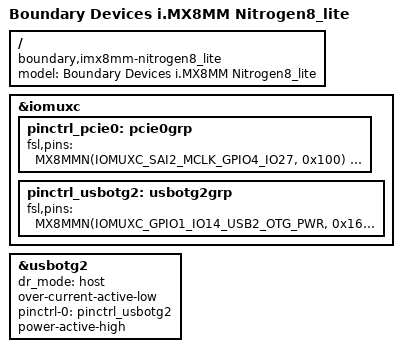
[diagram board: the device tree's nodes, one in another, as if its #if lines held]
// SPDX-License-Identifier: (GPL-2.0+ OR MIT)
/*
 * Copyright 2018 Boundary Devices
 */

/dts-v1/;
#ifdef CONFIG_DEFCONFIG
#define UBOOT
#endif
#define IMX8MM

#define MX8MMN(a, b)	MX8MM_##a b
#define IMX8MMN(a)	IMX8MM_##a
#define IMX8MN_CLK_LCDIF_PIXEL IMX8MN_CLK_DISP_PIXEL_ROOT
#include <dt-bindings/phy/phy-imx8-pcie.h>
#include "imx8mm.dtsi"
#include "imx8mmn-nitrogen8_lite.dtsi"

&iomuxc {
	pinctrl_pcie0: pcie0grp {
		fsl,pins = <
#define GP_PCIE0_RESET		<&gpio4 27 GPIO_ACTIVE_LOW>
			MX8MMN(IOMUXC_SAI2_MCLK_GPIO4_IO27, 0x100)
#define GP_PCIE0_DISABLE	<&gpio4 24 GPIO_ACTIVE_LOW>
			MX8MMN(IOMUXC_SAI2_TXFS_GPIO4_IO24, 0x100)
		>;
	};

	pinctrl_usbotg2: usbotg2grp {
		fsl,pins = <
			MX8MMN(IOMUXC_GPIO1_IO14_USB2_OTG_PWR, 0x16)
			MX8MMN(IOMUXC_GPIO1_IO15_USB2_OTG_OC, 0x156)
		>;
	};
};

/ {
	model = "Boundary Devices i.MX8MM Nitrogen8_lite";
	compatible = "boundary,imx8mm-nitrogen8_lite", "fsl,imx8mm";
};

#ifndef UBOOT
&csi1_bridge {
	fsl,mipi-mode;
	status = "okay";

	port {
		csi1_ep: endpoint {
			remote-endpoint = <&csi1_mipi_ep>;
		};
	};
};

&pcie0 {
	assigned-clocks = <&clk IMX8MM_CLK_PCIE1_AUX>,
			  <&clk IMX8MM_CLK_PCIE1_CTRL>;
	assigned-clock-parents = <&clk IMX8MM_SYS_PLL2_50M>,
				 <&clk IMX8MM_SYS_PLL2_250M>;
	assigned-clock-rates = <10000000>, <250000000>;
	clocks = <&clk IMX8MM_CLK_PCIE1_ROOT>,
		 <&clk IMX8MM_CLK_PCIE1_AUX>,
		 <&clk IMX8MM_CLK_PCIE1_PHY>;
	clock-names = "pcie", "pcie_aux", "pcie_bus";
	disable-gpio = GP_PCIE0_DISABLE;
	pinctrl-names = "default";
	pinctrl-0 = <&pinctrl_pcie0>;
	reset-gpio = GP_PCIE0_RESET;
	status = "okay";
};

&pcie_phy {
	clocks = <&clk IMX8MM_CLK_PCIE1_PHY>;
	clock-names = "ref";
	fsl,clkreq-unsupported;
	fsl,refclk-pad-mode = <IMX8_PCIE_REFCLK_PAD_OUTPUT>;
	fsl,tx-deemph-gen1 = <0x2d>;
	fsl,tx-deemph-gen2 = <0xf>;
	status = "okay";
};

&pgc_vpumix {
	dvfs-supply = <&reg_buck5>;
	idle-microvolt = <850000 805000 900000>;
};
#endif

&usbotg2 {
	dr_mode = "host";
	over-current-active-low;
	pinctrl-names = "default";
	pinctrl-0 = <&pinctrl_usbotg2>;
	power-active-high;
	status = "okay";
};

#ifndef UBOOT
&vpu_g1 {
	status = "okay";
};

&vpu_g2 {
	status = "okay";
};

&vpu_h1 {
	status = "okay";
};

&vpu_v4l2 {
	status = "okay";
};
#endif
